VERSION "created by canmatrix"

NS_ :

BS_:

BU_: brakelight_bspd_shutdown bms_core air_ctrl dashboard throttle

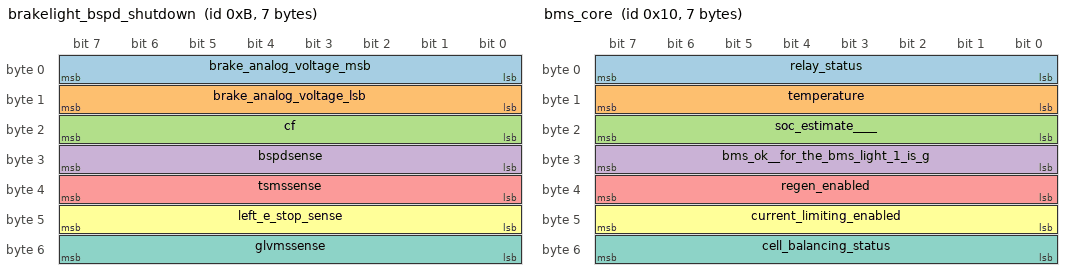
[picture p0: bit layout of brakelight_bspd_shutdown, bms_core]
BO_ 11 brakelight_bspd_shutdown: 7 brakelight_bspd_shutdown
 SG_ brake_analog_voltage_msb : 7|8@0+ (1,0) [0|1] "" air_ctrl, bms_core, dashboard, throttle
 SG_ brake_analog_voltage_lsb : 15|8@0+ (1,0) [0|1] "" air_ctrl, bms_core, dashboard, throttle
 SG_ cf : 23|8@0+ (1,0) [0|1] "" air_ctrl, bms_core, dashboard, throttle
 SG_ bspdsense : 31|8@0+ (1,0) [0|1] "" air_ctrl, bms_core, dashboard, throttle
 SG_ tsmssense : 39|8@0+ (1,0) [0|1] "" air_ctrl, bms_core, dashboard, throttle
 SG_ left_e_stop_sense : 47|8@0+ (1,0) [0|1] "" air_ctrl, bms_core, dashboard, throttle
 SG_ glvmssense : 55|8@0+ (1,0) [0|1] "" air_ctrl, bms_core, dashboard, throttle

BO_ 16 bms_core: 7 bms_core
 SG_ relay_status : 7|8@0+ (1,0) [0|1] "" air_ctrl, brakelight_bspd_shutdown, dashboard, throttle
 SG_ temperature : 15|8@0+ (1,0) [0|1] "" air_ctrl, brakelight_bspd_shutdown, dashboard, throttle
 SG_ soc_estimate____ : 23|8@0+ (1,0) [0|1] "" air_ctrl, brakelight_bspd_shutdown, dashboard, throttle
 SG_ bms_ok__for_the_bms_light_1_is_g : 31|8@0+ (1,0) [0|1] "" air_ctrl, brakelight_bspd_shutdown, dashboard, throttle
 SG_ regen_enabled : 39|8@0+ (1,0) [0|1] "" air_ctrl, brakelight_bspd_shutdown, dashboard, throttle
 SG_ current_limiting_enabled : 47|8@0+ (1,0) [0|1] "" air_ctrl, brakelight_bspd_shutdown, dashboard, throttle
 SG_ cell_balancing_status : 55|8@0+ (1,0) [0|1] "" air_ctrl, brakelight_bspd_shutdown, dashboard, throttle

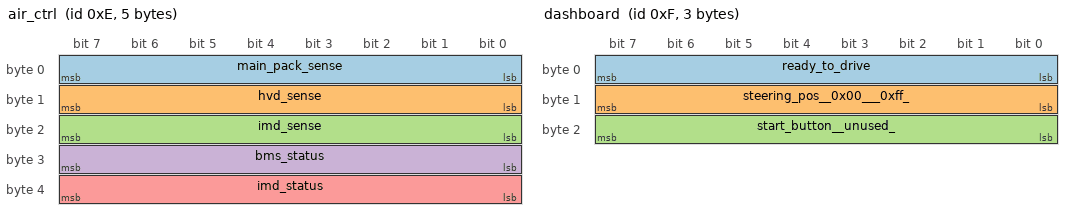
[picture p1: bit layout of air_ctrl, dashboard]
BO_ 14 air_ctrl: 5 air_ctrl
 SG_ main_pack_sense : 7|8@0+ (1,0) [0|1] "" bms_core, brakelight_bspd_shutdown, dashboard, throttle
 SG_ hvd_sense : 15|8@0+ (1,0) [0|1] "" bms_core, brakelight_bspd_shutdown, dashboard, throttle
 SG_ imd_sense : 23|8@0+ (1,0) [0|1] "" bms_core, brakelight_bspd_shutdown, dashboard, throttle
 SG_ bms_status : 31|8@0+ (1,0) [0|1] "" bms_core, brakelight_bspd_shutdown, dashboard, throttle
 SG_ imd_status : 39|8@0+ (1,0) [0|1] "" bms_core, brakelight_bspd_shutdown, dashboard, throttle

BO_ 15 dashboard: 3 dashboard
 SG_ ready_to_drive : 7|8@0+ (1,0) [0|1] "" air_ctrl, bms_core, brakelight_bspd_shutdown, throttle
 SG_ steering_pos__0x00___0xff_ : 15|8@0+ (1,0) [0|1] "" air_ctrl, bms_core, brakelight_bspd_shutdown, throttle
 SG_ start_button__unused_ : 23|8@0+ (1,0) [0|1] "" air_ctrl, bms_core, brakelight_bspd_shutdown, throttle

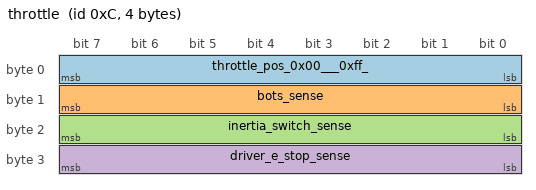
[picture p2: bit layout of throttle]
BO_ 12 throttle: 4 throttle
 SG_ throttle_pos_0x00___0xff_ : 7|8@0+ (1,0) [0|1] "" air_ctrl, bms_core, brakelight_bspd_shutdown, dashboard
 SG_ bots_sense : 15|8@0+ (1,0) [0|1] "" air_ctrl, bms_core, brakelight_bspd_shutdown, dashboard
 SG_ inertia_switch_sense : 23|8@0+ (1,0) [0|1] "" air_ctrl, bms_core, brakelight_bspd_shutdown, dashboard
 SG_ driver_e_stop_sense : 31|8@0+ (1,0) [0|1] "" air_ctrl, bms_core, brakelight_bspd_shutdown, dashboard

CM_ BO_ 11  "add comment here";
CM_ BO_ 16  "add comment here";
CM_ BO_ 14  "add comment here";
CM_ BO_ 15  "add comment here";
CM_ BO_ 12  "add comment here";

CM_ BU_ brakelight_bspd_shutdown "more comments can go here";
CM_ BU_ bms_core "more comments can go here";
CM_ BU_ air_ctrl "more comments can go here";
CM_ BU_ dashboard "more comments can go here";
CM_ BU_ throttle "more comments can go here";

BA_DEF_ SG_ "SystemSignalLongSymbol" STRING;

BA_ "SystemSignalLongSymbol" SG_ 16 bms_ok__for_the_bms_light_1_is_g "bms_ok_(for_the_bms_light)1_is_good0_is_bad";
